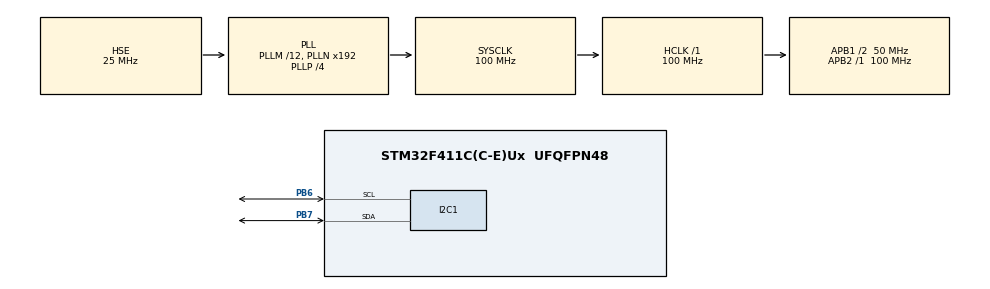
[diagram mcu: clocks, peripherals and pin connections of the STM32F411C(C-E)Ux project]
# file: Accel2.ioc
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I2C1.I2C_Mode=I2C_Standard
Mcu.Family=STM32F4
Mcu.Name=STM32F411C(C-E)Ux
Mcu.Package=UFQFPN48
NVIC.PriorityGroup=NVIC_PRIORITYGROUP_4
PB6.GPIO_Pu=GPIO_PULLUP
PB6.Mode=I2C
PB6.Signal=I2C1_SCL
PB7.GPIO_Pu=GPIO_PULLUP
PB7.Mode=I2C
PB7.Signal=I2C1_SDA
PH0\ -\ OSC_IN.Mode=HSE-External-Oscillator
PH0\ -\ OSC_IN.Signal=RCC_OSC_IN
PH1\ -\ OSC_OUT.Mode=HSE-External-Oscillator
PH1\ -\ OSC_OUT.Signal=RCC_OSC_OUT
ProjectManager.HeapSize=0x200
ProjectManager.StackSize=0x400
ProjectManager.TargetToolchain=STM32CubeIDE
RCC.48MHZClocksFreq_Value=100000000
RCC.AHBFreq_Value=100000000
RCC.APB1CLKDivider=RCC_HCLK_DIV2
RCC.APB1Freq_Value=50000000
RCC.APB1TimFreq_Value=100000000
RCC.APB2Freq_Value=100000000
RCC.APB2TimFreq_Value=100000000
RCC.CortexFreq_Value=100000000
RCC.HCLKFreq_Value=100000000
RCC.HSE_VALUE=25000000
RCC.HSI_VALUE=16000000
RCC.LSE_VALUE=32768
RCC.PLLM=12
RCC.PLLP=RCC_PLLP_DIV4
RCC.PLLSourceVirtual=RCC_PLLSOURCE_HSE
RCC.SYSCLKFreq_VALUE=100000000
RCC.SYSCLKSource=RCC_SYSCLKSOURCE_PLLCLK
RCC.VCOOutputFreq_Value=400000000
board=custom

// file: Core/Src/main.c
/* USER CODE BEGIN Header */
/**
  ******************************************************************************
  * @file           : main.c
  * @brief          : Main program body
  ******************************************************************************
  * @attention
  *
  * <h2><center>&copy; Copyright (c) 2021 STMicroelectronics.
  * All rights reserved.</center></h2>
  *
  * This software component is licensed by ST under BSD 3-Clause license,
  * the "License"; You may not use this file except in compliance with the
  * License. You may obtain a copy of the License at:
  *                        opensource.org/licenses/BSD-3-Clause
  *
  ******************************************************************************
  */
/* USER CODE END Header */
#include "main.h"

/* USER CODE BEGIN PTD */
typedef enum{
	MOVE_WAIT = 0,
	LED_ON = 1
}ledStateType;

typedef struct{
	float Xaccel;
	float Yaccel;
	float Zaccel;
}accelsDataType;

typedef struct{
	float Xaccel;
	float Yaccel;
	float Zaccel;
}prevAccelsDataType;
/* USER CODE END PTD */

/* USER CODE BEGIN PD */
#define FIFO_CTRL 0x2E

#define OUT_X_L_A 0x28
#define OUT_X_H_A 0x29

#define OUT_Y_L_A 0x2A
#define OUT_Y_H_A 0x2B

#define OUT_Z_L_A 0x2C
#define OUT_Z_H_A 0x2D

#define CTRL_REG4 0x1E
#define CTRL_REG1_A 0x20
#define CTRL_REG5_XL 0x1F

#define INT_GEN_THS_Z_XL 0x09
#define INT_GEN_THS_Y_XL 0x08
#define INT_GEN_THS_X_XL 0x07
#define INT_GEN_CFG_XL 0x06
#define INT1_CTRL 0x0C
/* USER CODE END PD */

I2C_HandleTypeDef hi2c1;
uint16_t cmd;

void SystemClock_Config(void);
static void MX_GPIO_Init(void);
static void MX_I2C1_Init(void);
void lsm303CInit(void);
void getAccels(accelsDataType *accelsData);
void getFirstAccels(prevAccelsDataType *prevAccelsData);
uint16_t movementDetection(prevAccelsDataType *prevAccelsData, accelsDataType *accelsData);

int main(void)
{
	accelsDataType accelsData;
	static prevAccelsDataType prevAccelsData = {0.0F, 0.0F, 0.0F};

  /* MCU Configuration--------------------------------------------------------*/

  /* Reset of all peripherals, Initializes the Flash interface and the Systick. */
  HAL_Init();

  /* Configure the system clock */
  SystemClock_Config();

  /* Initialize all configured peripherals */
  MX_GPIO_Init();
  MX_I2C1_Init();
  lsm303CInit();
  /* USER CODE BEGIN 2 */
  getFirstAccels(&prevAccelsData);
  /* USER CODE END 2 */

  /* Infinite loop */
  while (1)
  {
	  getAccels(&accelsData);
	  movementDetection(&prevAccelsData, &accelsData);
  }
}

void SystemClock_Config(void)
{
  RCC_OscInitTypeDef RCC_OscInitStruct = {0};
  RCC_ClkInitTypeDef RCC_ClkInitStruct = {0};

  /** Configure the main internal regulator output voltage
  */
  __HAL_RCC_PWR_CLK_ENABLE();
  __HAL_PWR_VOLTAGESCALING_CONFIG(PWR_REGULATOR_VOLTAGE_SCALE1);
  /** Initializes the RCC Oscillators according to the specified parameters
  * in the RCC_OscInitTypeDef structure.
  */
  RCC_OscInitStruct.OscillatorType = RCC_OSCILLATORTYPE_HSE;
  RCC_OscInitStruct.HSEState = RCC_HSE_ON;
  RCC_OscInitStruct.PLL.PLLState = RCC_PLL_ON;
  RCC_OscInitStruct.PLL.PLLSource = RCC_PLLSOURCE_HSE;
  RCC_OscInitStruct.PLL.PLLM = 12;
  RCC_OscInitStruct.PLL.PLLN = 192;
  RCC_OscInitStruct.PLL.PLLP = RCC_PLLP_DIV4;
  RCC_OscInitStruct.PLL.PLLQ = 4;
  if (HAL_RCC_OscConfig(&RCC_OscInitStruct) != HAL_OK)
  {
    Error_Handler();
  }
  /** Initializes the CPU, AHB and APB buses clocks
  */
  RCC_ClkInitStruct.ClockType = RCC_CLOCKTYPE_HCLK|RCC_CLOCKTYPE_SYSCLK
                              |RCC_CLOCKTYPE_PCLK1|RCC_CLOCKTYPE_PCLK2;
  RCC_ClkInitStruct.SYSCLKSource = RCC_SYSCLKSOURCE_PLLCLK;
  RCC_ClkInitStruct.AHBCLKDivider = RCC_SYSCLK_DIV1;
  RCC_ClkInitStruct.APB1CLKDivider = RCC_HCLK_DIV2;
  RCC_ClkInitStruct.APB2CLKDivider = RCC_HCLK_DIV1;

  if (HAL_RCC_ClockConfig(&RCC_ClkInitStruct, FLASH_LATENCY_3) != HAL_OK)
  {
    Error_Handler();
  }
}

static void MX_I2C1_Init(void)
{

  hi2c1.Instance = I2C1;
  hi2c1.Init.ClockSpeed = 100000;
  hi2c1.Init.DutyCycle = I2C_DUTYCYCLE_2;
  hi2c1.Init.OwnAddress1 = 0;
  hi2c1.Init.AddressingMode = I2C_ADDRESSINGMODE_7BIT;
  hi2c1.Init.DualAddressMode = I2C_DUALADDRESS_DISABLE;
  hi2c1.Init.OwnAddress2 = 0;
  hi2c1.Init.GeneralCallMode = I2C_GENERALCALL_DISABLE;
  hi2c1.Init.NoStretchMode = I2C_NOSTRETCH_DISABLE;
  if (HAL_I2C_Init(&hi2c1) != HAL_OK)
  {
    Error_Handler();
  }

}

//Настройка режима работы чипа акселерометра
void lsm303CInit(void)
{
	uint8_t DevAddress;
	uint16_t writeData;

	DevAddress = 0x3A;
	writeData = CTRL_REG1_A;
	writeData = (uint16_t)writeData | ((uint16_t)0x17 << 8);
	HAL_I2C_Master_Transmit(&hi2c1, DevAddress, (uint8_t *)(&writeData), 2, 1000);
	return;
}

void getAccels(accelsDataType *accelsData)
{
	int16_t accel_X, accel_Y, accel_Z;
	uint8_t DevAddress;
	uint8_t data;
	uint8_t RdataL, RdataH;
	float accelX, accelY, accelZ;

	DevAddress = 0x3A; //Адрес акселерометра по умолчанию

	//Ускорение по оси X
	data = OUT_X_L_A;
	HAL_I2C_Master_Transmit(&hi2c1, DevAddress, (uint8_t *)(&data), 1, 1000);
	HAL_I2C_Master_Receive(&hi2c1, DevAddress, (uint8_t *)&RdataL, 1, 1000);

	data = OUT_X_H_A;
	HAL_I2C_Master_Transmit(&hi2c1, DevAddress, (uint8_t *)(&data), 1, 1000);
	HAL_I2C_Master_Receive(&hi2c1, DevAddress, (uint8_t *)&RdataH, 1, 1000);

	accel_X = (int16_t)((uint16_t)RdataL | ((uint16_t)RdataH << 8));
	accelX = (2.0 / 32767) * accel_X; //Ускорение по оси X

	//Ускорение по оси Y
	data = OUT_Y_L_A;
	HAL_I2C_Master_Transmit(&hi2c1, DevAddress, (uint8_t *)(&data), 1, 1000);
	HAL_I2C_Master_Receive(&hi2c1, DevAddress, (uint8_t *)&RdataL, 1, 1000);

	data = OUT_Y_H_A;
	HAL_I2C_Master_Transmit(&hi2c1, DevAddress, (uint8_t *)(&data), 1, 1000);
	HAL_I2C_Master_Receive(&hi2c1, DevAddress, (uint8_t *)&RdataH, 1, 1000);

	accel_Y = (int16_t)((uint16_t)RdataL | ((uint16_t)RdataH << 8));
	accelY = (2.0 / 32767) * accel_Y; //Ускорение по оси Y

	//Ускорение по оси Z
	data = OUT_Z_L_A;
    HAL_I2C_Master_Transmit(&hi2c1, DevAddress, (uint8_t *)(&data), 1, 1000);
	HAL_I2C_Master_Receive(&hi2c1, DevAddress, (uint8_t *)&RdataL, 1, 1000);

	data = OUT_Z_H_A;
	HAL_I2C_Master_Transmit(&hi2c1, DevAddress, (uint8_t *)(&data), 1, 1000);
	HAL_I2C_Master_Receive(&hi2c1, DevAddress, (uint8_t *)&RdataH, 1, 1000);

	accel_Z = (int16_t)((uint16_t)RdataL | ((uint16_t)RdataH << 8));
	accelZ = (2.0 / 32767) * accel_Z; //Ускорение по оси Y

	accelsData->Xaccel = accelX;
	accelsData->Yaccel = accelY;
	accelsData->Zaccel = accelZ;
}

void getFirstAccels(prevAccelsDataType *prevAccelsData)
{
	accelsDataType accelsData;

	getAccels(&accelsData);
	prevAccelsData->Xaccel = accelsData.Xaccel;
	prevAccelsData->Yaccel = accelsData.Yaccel;
	prevAccelsData->Zaccel = accelsData.Zaccel;
}

uint16_t movementDetection(prevAccelsDataType *prevAccelsData, accelsDataType *accelsData)
{
	int16_t prevX, prevY, prevZ;
	int16_t newX, newY, newZ;
	int16_t moveFlg;

	moveFlg = 0;

	prevX = (int16_t)(prevAccelsData->Xaccel * 10.0F + 0.5F);
	prevY = (int16_t)(prevAccelsData->Yaccel * 10.0F + 0.5F);
	prevZ = (int16_t)(prevAccelsData->Zaccel * 10.0F + 0.5F);

	newX = (int16_t)(accelsData->Xaccel * 10.0F + 0.5F);
	newY = (int16_t)(accelsData->Yaccel * 10.0F + 0.5F);
	newZ = (int16_t)(accelsData->Zaccel * 10.0F + 0.5F);

	if(prevX != newX){
		moveFlg = 1;
		prevAccelsData->Xaccel = accelsData->Xaccel;
	}

	if(prevY != newY){
		moveFlg = 1;
		prevAccelsData->Yaccel = accelsData->Yaccel;
	}

	if(prevZ != newZ){
		moveFlg = 1;
		prevAccelsData->Zaccel = accelsData->Zaccel;
	}

	return(moveFlg);
}

static void MX_GPIO_Init(void)
{

  /* GPIO Ports Clock Enable */
  __HAL_RCC_GPIOH_CLK_ENABLE();
  __HAL_RCC_GPIOB_CLK_ENABLE();

}

void Error_Handler(void)
{
  __disable_irq();
  while (1)
  {
  }
}

/************************ (C) COPYRIGHT STMicroelectronics *****END OF FILE****/
